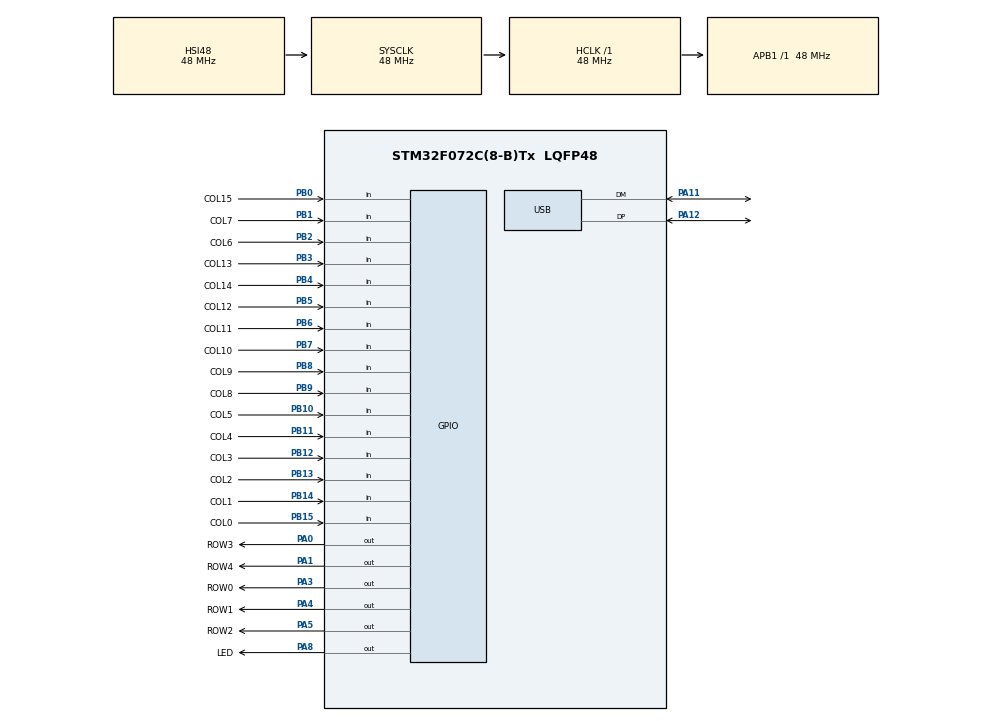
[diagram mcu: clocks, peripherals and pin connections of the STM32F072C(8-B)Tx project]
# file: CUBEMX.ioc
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Mcu.Family=STM32F0
Mcu.Name=STM32F072C(8-B)Tx
Mcu.Package=LQFP48
PA0.GPIO_Label=ROW3
PA0.Signal=GPIO_Output
PA1.GPIO_Label=ROW4
PA1.Signal=GPIO_Output
PA11.Mode=Device
PA11.Signal=USB_DM
PA12.Mode=Device
PA12.Signal=USB_DP
PA13.Mode=Serial_Wire
PA13.Signal=SYS_SWDIO
PA14.Mode=Serial_Wire
PA14.Signal=SYS_SWCLK
PA3.GPIO_Label=ROW0
PA3.Signal=GPIO_Output
PA4.GPIO_Label=ROW1
PA4.Signal=GPIO_Output
PA5.GPIO_Label=ROW2
PA5.Signal=GPIO_Output
PA8.GPIO_Label=LED
PA8.PinState=GPIO_PIN_SET
PA8.Signal=GPIO_Output
PB0.GPIO_Label=COL15
PB0.GPIO_PuPd=GPIO_PULLDOWN
PB0.Signal=GPIO_Input
PB1.GPIO_Label=COL7
PB1.GPIO_PuPd=GPIO_PULLDOWN
PB1.Signal=GPIO_Input
PB10.GPIO_Label=COL5
PB10.GPIO_PuPd=GPIO_PULLDOWN
PB10.Signal=GPIO_Input
PB11.GPIO_Label=COL4
PB11.GPIO_PuPd=GPIO_PULLDOWN
PB11.Signal=GPIO_Input
PB12.GPIO_Label=COL3
PB12.GPIO_PuPd=GPIO_PULLDOWN
PB12.Signal=GPIO_Input
PB13.GPIO_Label=COL2
PB13.GPIO_PuPd=GPIO_PULLDOWN
PB13.Signal=GPIO_Input
PB14.GPIO_Label=COL1
PB14.GPIO_PuPd=GPIO_PULLDOWN
PB14.Signal=GPIO_Input
PB15.GPIO_Label=COL0
PB15.GPIO_PuPd=GPIO_PULLDOWN
PB15.Signal=GPIO_Input
PB2.GPIO_Label=COL6
PB2.GPIO_PuPd=GPIO_PULLDOWN
PB2.Signal=GPIO_Input
PB3.GPIO_Label=COL13
PB3.GPIO_PuPd=GPIO_PULLDOWN
PB3.Signal=GPIO_Input
PB4.GPIO_Label=COL14
PB4.GPIO_PuPd=GPIO_PULLDOWN
PB4.Signal=GPIO_Input
PB5.GPIO_Label=COL12
PB5.GPIO_PuPd=GPIO_PULLDOWN
PB5.Signal=GPIO_Input
PB6.GPIO_Label=COL11
PB6.GPIO_PuPd=GPIO_PULLDOWN
PB6.Signal=GPIO_Input
PB7.GPIO_Label=COL10
PB7.GPIO_PuPd=GPIO_PULLDOWN
PB7.Signal=GPIO_Input
PB8.GPIO_Label=COL9
PB8.GPIO_PuPd=GPIO_PULLDOWN
PB8.Signal=GPIO_Input
PB9.GPIO_Label=COL8
PB9.GPIO_PuPd=GPIO_PULLDOWN
PB9.Signal=GPIO_Input
ProjectManager.HeapSize=0x200
ProjectManager.StackSize=0x400
ProjectManager.TargetToolchain=MDK-ARM V5
RCC.AHBFreq_Value=48000000
RCC.APB1Freq_Value=48000000
RCC.APB1TimFreq_Value=48000000
RCC.HCLKFreq_Value=48000000
RCC.SYSCLKFreq_VALUE=48000000
RCC.SYSCLKSource=RCC_SYSCLKSOURCE_HSI48
board=custom

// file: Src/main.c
/* USER CODE BEGIN Header */
/**
  ******************************************************************************
  * @file           : main.c
  * @brief          : Main program body
  ******************************************************************************
  * @attention
  *
  * <h2><center>&copy; Copyright (c) 2019 STMicroelectronics.
  * All rights reserved.</center></h2>
  *
  * This software component is licensed by ST under BSD 3-Clause license,
  * the "License"; You may not use this file except in compliance with the
  * License. You may obtain a copy of the License at:
  *                        opensource.org/licenses/BSD-3-Clause
  *
  ******************************************************************************
  */
/* USER CODE END Header */

#include "main.h"

PCD_HandleTypeDef hpcd_USB_FS;

void (*SysMemBootJump) (void);
void BootloaderInit(void);
void SystemClock_Config(void);
static void MX_GPIO_Init(void);
static void MX_USB_PCD_Init(void);

/* USER CODE BEGIN 0 */

/** Activate the bootloader without BOOT* pins
*/
void GoToDFU(void)
{
  /* Resets the RCC clock configuration to the default reset state */
  HAL_RCC_DeInit();

  /* de-Initialize common part of the HAL and stop the systick */
  HAL_DeInit();

  /* Point the PC to the SystemMemory reset vector (+4) */
  SysMemBootJump = (void (*) (void)) (*((uint32_t *) (0x1FFFC800 + 4)));

  /* Set the main stack pointer to its default value */
  __set_MSP(0x20002250);

  /* Call the STM32 SystemMemory Bootloader */
  SysMemBootJump();

  /* wait until reset */
  for(;;)
  {
    __NOP();
  }
}

/* USER CODE END 0 */

int main(void)
{
  /* USER CODE BEGIN 1 */
	static int a = 0;

  /* USER CODE END 1 */

  /* MCU Configuration--------------------------------------------------------*/

  /* Reset of all peripherals, Initializes the Flash interface and the Systick. */
  HAL_Init();

  /* Configure the system clock */
  SystemClock_Config();

  /* Initialize all configured peripherals */
  MX_GPIO_Init();
  MX_USB_PCD_Init();

  /* Infinite loop */
  while (1)
  {
    /* USER CODE BEGIN 3 */
		HAL_Delay(500);
		HAL_GPIO_TogglePin(LED_GPIO_Port, LED_Pin);

		//Enter DFU after a while
		if(a++ >= 10) GoToDFU();
  }
  /* USER CODE END 3 */
}

void SystemClock_Config(void)
{
  RCC_OscInitTypeDef RCC_OscInitStruct = {0};
  RCC_ClkInitTypeDef RCC_ClkInitStruct = {0};
  RCC_PeriphCLKInitTypeDef PeriphClkInit = {0};

  /** Initializes the CPU, AHB and APB busses clocks
  */
  RCC_OscInitStruct.OscillatorType = RCC_OSCILLATORTYPE_HSI48;
  RCC_OscInitStruct.HSI48State = RCC_HSI48_ON;
  RCC_OscInitStruct.PLL.PLLState = RCC_PLL_NONE;
  if (HAL_RCC_OscConfig(&RCC_OscInitStruct) != HAL_OK)
  {
    Error_Handler();
  }
  /** Initializes the CPU, AHB and APB busses clocks
  */
  RCC_ClkInitStruct.ClockType = RCC_CLOCKTYPE_HCLK|RCC_CLOCKTYPE_SYSCLK
                              |RCC_CLOCKTYPE_PCLK1;
  RCC_ClkInitStruct.SYSCLKSource = RCC_SYSCLKSOURCE_HSI48;
  RCC_ClkInitStruct.AHBCLKDivider = RCC_SYSCLK_DIV1;
  RCC_ClkInitStruct.APB1CLKDivider = RCC_HCLK_DIV1;

  if (HAL_RCC_ClockConfig(&RCC_ClkInitStruct, FLASH_LATENCY_1) != HAL_OK)
  {
    Error_Handler();
  }
  PeriphClkInit.PeriphClockSelection = RCC_PERIPHCLK_USB;
  PeriphClkInit.UsbClockSelection = RCC_USBCLKSOURCE_HSI48;

  if (HAL_RCCEx_PeriphCLKConfig(&PeriphClkInit) != HAL_OK)
  {
    Error_Handler();
  }
}

static void MX_USB_PCD_Init(void)
{

  hpcd_USB_FS.Instance = USB;
  hpcd_USB_FS.Init.dev_endpoints = 8;
  hpcd_USB_FS.Init.speed = PCD_SPEED_FULL;
  hpcd_USB_FS.Init.phy_itface = PCD_PHY_EMBEDDED;
  hpcd_USB_FS.Init.low_power_enable = DISABLE;
  hpcd_USB_FS.Init.lpm_enable = DISABLE;
  hpcd_USB_FS.Init.battery_charging_enable = DISABLE;
  if (HAL_PCD_Init(&hpcd_USB_FS) != HAL_OK)
  {
    Error_Handler();
  }

}

static void MX_GPIO_Init(void)
{
  GPIO_InitTypeDef GPIO_InitStruct = {0};

  /* GPIO Ports Clock Enable */
  __HAL_RCC_GPIOC_CLK_ENABLE();
  __HAL_RCC_GPIOF_CLK_ENABLE();
  __HAL_RCC_GPIOA_CLK_ENABLE();
  __HAL_RCC_GPIOB_CLK_ENABLE();

  /*Configure GPIO pin Output Level */
  HAL_GPIO_WritePin(GPIOA, ROW3_Pin|ROW4_Pin|ROW0_Pin|ROW1_Pin
                          |ROW2_Pin, GPIO_PIN_RESET);

  /*Configure GPIO pin Output Level */
  HAL_GPIO_WritePin(LED_GPIO_Port, LED_Pin, GPIO_PIN_SET);

  /*Configure GPIO pins : PC13 PC14 PC15 */
  GPIO_InitStruct.Pin = GPIO_PIN_13|GPIO_PIN_14|GPIO_PIN_15;
  GPIO_InitStruct.Mode = GPIO_MODE_ANALOG;
  GPIO_InitStruct.Pull = GPIO_NOPULL;
  HAL_GPIO_Init(GPIOC, &GPIO_InitStruct);

  /*Configure GPIO pins : PF0 PF1 */
  GPIO_InitStruct.Pin = GPIO_PIN_0|GPIO_PIN_1;
  GPIO_InitStruct.Mode = GPIO_MODE_ANALOG;
  GPIO_InitStruct.Pull = GPIO_NOPULL;
  HAL_GPIO_Init(GPIOF, &GPIO_InitStruct);

  /*Configure GPIO pins : ROW3_Pin ROW4_Pin ROW0_Pin ROW1_Pin
                           ROW2_Pin LED_Pin */
  GPIO_InitStruct.Pin = ROW3_Pin|ROW4_Pin|ROW0_Pin|ROW1_Pin
                          |ROW2_Pin|LED_Pin;
  GPIO_InitStruct.Mode = GPIO_MODE_OUTPUT_PP;
  GPIO_InitStruct.Pull = GPIO_NOPULL;
  GPIO_InitStruct.Speed = GPIO_SPEED_FREQ_LOW;
  HAL_GPIO_Init(GPIOA, &GPIO_InitStruct);

  /*Configure GPIO pins : PA2 PA6 PA7 PA9
                           PA10 PA15 */
  GPIO_InitStruct.Pin = GPIO_PIN_2|GPIO_PIN_6|GPIO_PIN_7|GPIO_PIN_9
                          |GPIO_PIN_10|GPIO_PIN_15;
  GPIO_InitStruct.Mode = GPIO_MODE_ANALOG;
  GPIO_InitStruct.Pull = GPIO_NOPULL;
  HAL_GPIO_Init(GPIOA, &GPIO_InitStruct);

  /*Configure GPIO pins : COL15_Pin COL7_Pin COL6_Pin COL5_Pin
                           COL4_Pin COL3_Pin COL2_Pin COL1_Pin
                           COL0_Pin COL13_Pin COL14_Pin COL12_Pin
                           COL11_Pin COL10_Pin COL9_Pin COL8_Pin */
  GPIO_InitStruct.Pin = COL15_Pin|COL7_Pin|COL6_Pin|COL5_Pin
                          |COL4_Pin|COL3_Pin|COL2_Pin|COL1_Pin
                          |COL0_Pin|COL13_Pin|COL14_Pin|COL12_Pin
                          |COL11_Pin|COL10_Pin|COL9_Pin|COL8_Pin;
  GPIO_InitStruct.Mode = GPIO_MODE_INPUT;
  GPIO_InitStruct.Pull = GPIO_PULLDOWN;
  HAL_GPIO_Init(GPIOB, &GPIO_InitStruct);

}

void Error_Handler(void)
{
}

/************************ (C) COPYRIGHT STMicroelectronics *****END OF FILE****/
